# LPC12D27 register map
File version: 3
Registers are 32-bit, read-write, reset 0x0 unless marked. A register's access mark holds for its fields unless they carry their own. Offsets are from the block's base; [hi:lo] are bit positions; {n}, {i} and the like mark numbered series.

## SSP — Product name title=UM10441 Chapter title=LPC122x SSP controller Modification date=2/10/2011 Major revision=0 Minor revision=17
Base 0x40040000
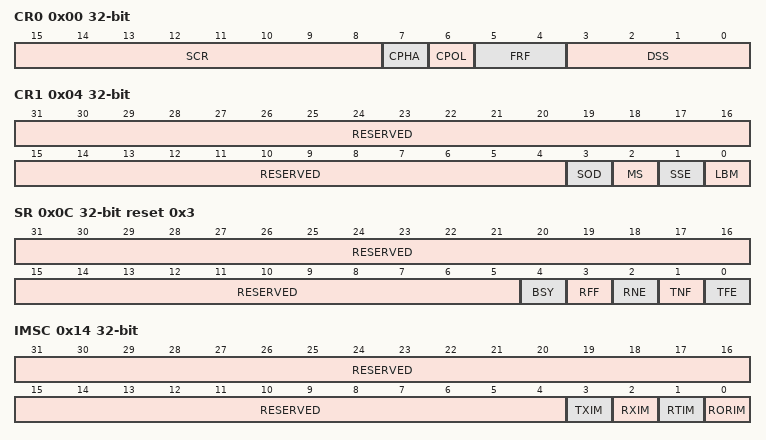
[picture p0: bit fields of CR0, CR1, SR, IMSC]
0x00 CR0 — Control Register 0. Selects the serial clock rate, bus type, and data size.
  [15:8] SCR — Serial Clock Rate. The number of prescaler-output clocks per bit on the bus, minus one. Given that CPSDVSR is the prescale divider, and the APB clock PCLK clocks the prescaler, the bit frequency is PCLK / (CPSDVSR x [SCR+1]).
  [7] CPHA — Clock Out Phase. This bit is only used in SPI mode.
    0=FIRSTCLOCK (SSP controller captures serial data on the first clock transition of the frame, that is, the transition away from the inter-frame state of the clock line.); 1=SECONDCLOCK (SSP controller captures serial data on the second clock transition of the frame, that is, the transition back to the inter-frame state of the clock line.)
  [6] CPOL — Clock Out Polarity. This bit is only used in SPI mode.
    0=LOW (SSP controller maintains the bus clock low between frames.); 1=HIGH (SSP controller maintains the bus clock high between frames.)
  [5:4] FRF — Frame Format.
    0=SPI; 1=TI; 2=MICROWIRE; 3=RESERVED (This combination is not supported and should not be used.)
  [3:0] DSS — Data Size Select. This field controls the number of bits transferred in each frame. Values 0000-0010 are not supported and should not be used.
    {v}={v+1}_BIT_TRANSFER (v=3..15)
0x04 CR1 — Control Register 1. Selects master/slave and other modes.
  [31:4] RESERVED — Reserved, user software should not write ones to reserved bits. The value read from a reserved bit is not defined.
  [3] SOD — Slave Output Disable. This bit is relevant only in slave mode (MS = 1). If it is 1, this blocks this SSP controller from driving the transmit data line (MISO).
  [2] MS — Master/Slave Mode.This bit can only be written when the SSE bit is 0.
    0=MASTER (The SSP controller acts as a master on the bus, driving the SCLK, MOSI, and SSEL lines and receiving the MISO line.); 1=SLAVE (The SSP controller acts as a slave on the bus, driving MISO line and receiving SCLK, MOSI, and SSEL lines.)
  [1] SSE — SSP Enable.
    0=DISABLED (The SSP controller is disabled.); 1=ENABLED (The SSP controller will interact with other devices on the serial bus. Software should write the appropriate control information to the other SSP registers and interrupt controller registers, before setting this bit.)
  [0] LBM — Loop Back Mode.
    0=NORMAL (During normal operation.); 1=OUTPUT (Serial input is taken from the serial output (MOSI or MISO) rather than the serial input pin (MISO or MOSI respectively).)
0x08 DR — Data Register. Writes fill the transmit FIFO, and reads empty the receive FIFO.
  [15:0] DATA — Write: software can write data to be sent in a future frame to this register whenever the TNF bit in the Status register is 1, indicating that the Tx FIFO is not full. If the Tx FIFO was previously empty and the SSP controller is not busy on the bus, transmission of the data will begin immediately. Otherwise the data written to this register will be sent as soon as all previous data has been sent (and received). If the data length is less than 16 bit, software must right-justify the data written to this register. Read: software can read data from this register whenever the RNE bit in the Status register is 1, indicating that the Rx FIFO is not empty. When software reads this register, the SSP controller returns data from the least recent frame in the Rx FIFO. If the data length is less than 16 bit, the data is right-justified in this field with higher order bits filled with 0s.
0x0C SR ro reset 0x3 — Status Register
  [31:5] RESERVED — Reserved, user software should not write ones to reserved bits. The value read from a reserved bit is not defined.
  [4] BSY — Busy. This bit is 0 if the SSP controller is idle, or 1 if it is currently sending/receiving a frame and/or the Tx FIFO is not empty.
  [3] RFF — Receive FIFO Full. This bit is 1 if the Receive FIFO is full, 0 if not.
  [2] RNE — Receive FIFO Not Empty. This bit is 0 if the Receive FIFO is empty, 1 if not.
  [1] TNF — Transmit FIFO Not Full. This bit is 0 if the Tx FIFO is full, 1 if not.
  [0] TFE — Transmit FIFO Empty. This bit is 1 is the Transmit FIFO is empty, 0 if not.
0x10 CPSR — Clock Prescale Register
  [7:0] CPSDVSR — This even value between 2 and 254, by which SSP_PCLK is divided to yield the prescaler output clock. Bit 0 always reads as 0.
0x14 IMSC — Interrupt Mask Set and Clear Register
  [31:4] RESERVED — Reserved, user software should not write ones to reserved bits. The value read from a reserved bit is not defined.
  [3] TXIM — Software should set this bit to enable interrupt when the Tx FIFO is at least half empty.
  [2] RXIM — Software should set this bit to enable interrupt when the Rx FIFO is at least half full.
  [1] RTIM — Software should set this bit to enable interrupt when a Receive Timeout condition occurs. A Receive Timeout occurs when the Rx FIFO is not empty, and no has not been read for a "timeout period". The timeout period is the same for master and slave modes and is determined by the SSP bit rate: 32 bits at PCLK / (CPSDVSR x [SCR+1]).
  [0] RORIM — Software should set this bit to enable interrupt when a Receive Overrun occurs, that is, when the Rx FIFO is full and another frame is completely received. The ARM spec implies that the preceding frame data is overwritten by the new frame data when this occurs.
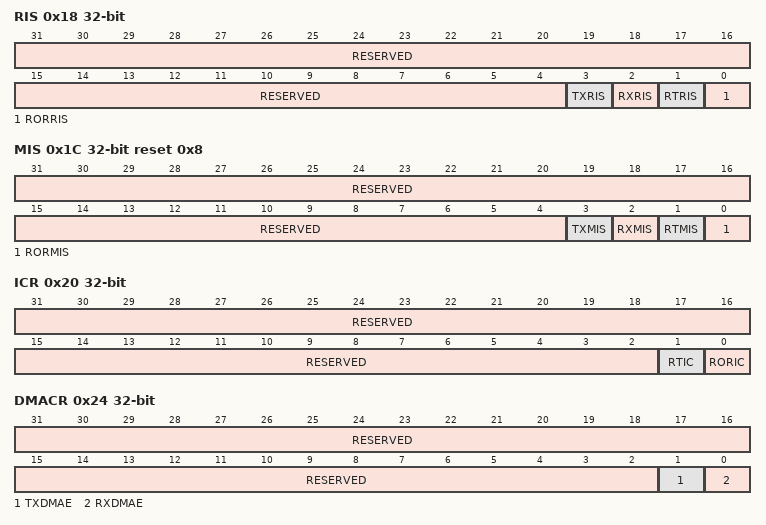
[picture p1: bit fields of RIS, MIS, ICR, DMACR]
0x18 RIS ro — Raw Interrupt Status Register
  [31:4] RESERVED — Reserved, user software should not write ones to reserved bits. The value read from a reserved bit is not defined.
  [3] TXRIS — This bit is 1 if the Tx FIFO is at least half empty.
  [2] RXRIS — This bit is 1 if the Rx FIFO is at least half full.
  [1] RTRIS — This bit is 1 if the Rx FIFO is not empty, and has not been read for a "timeout period". The timeout period is the same for master and slave modes and is determined by the SSP bit rate: 32 bits at PCLK / (CPSDVSR x [SCR+1]).
  [0] RORRIS — This bit is 1 if another frame was completely received while the RxFIFO was full. The ARM spec implies that the preceding frame data is overwritten by the new frame data when this occurs.
0x1C MIS ro reset 0x8 — Masked Interrupt Status Register
  [31:4] RESERVED — Reserved, user software should not write ones to reserved bits. The value read from a reserved bit is not defined.
  [3] TXMIS — This bit is 1 if the Tx FIFO is at least half empty, and this interrupt is enabled.
  [2] RXMIS — This bit is 1 if the Rx FIFO is at least half full, and this interrupt is enabled.
  [1] RTMIS — This bit is 1 if the Rx FIFO is not empty, has not been read for a "timeout period", and this interrupt is enabled. The timeout period is the same for master and slave modes and is determined by the SSP bit rate: 32 bits at PCLK / (CPSDVSR x [SCR+1]).
  [0] RORMIS — This bit is 1 if another frame was completely received while the RxFIFO was full, and this interrupt is enabled.
0x20 ICR wo — SSPICR Interrupt Clear Register
  [31:2] RESERVED — Reserved, user software should not write ones to reserved bits. The value read from a reserved bit is not defined.
  [1] RTIC — Writing a 1 to this bit clears the "Rx FIFO was not empty and has not been read for a timeout period" interrupt. The timeout period is the same for master and slave modes and is determined by the SSP bit rate: 32 bits at PCLK / (CPSDVSR x [SCR+1]).
  [0] RORIC — Writing a 1 to this bit clears the "frame was received when RxFIFO was full" interrupt.
0x24 DMACR — DMA Control Register
  [31:2] RESERVED — Reserved, user software should not write ones to reserved bits. The value read from a reserved bit is not defined.
  [1] TXDMAE — Transmit DMA Enable
    0=DISABLED (Transmit DMA disabled.); 1=ENABLED (DMA for the transmit FIFO is enabled.)
  [0] RXDMAE — Receive DMA Enable
    0=DISABLED (Receive DMA disabled.); 1=ENABLED (DMA for the receive FIFO is enabled.)
